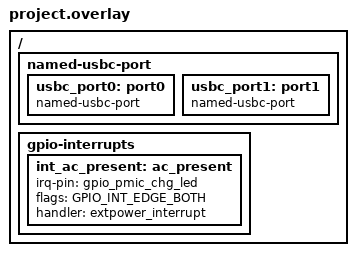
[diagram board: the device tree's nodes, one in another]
/* Copyright 2025 The ChromiumOS Authors
 * Use of this source code is governed by a BSD-style license that can be
 * found in the LICENSE file.
 */

/* bluey program common DTS includes */

#include <cros/integrated_fwid.dtsi>

#include "../interrupts.dtsi"
#include "../adc.dtsi"
#include "../i2c.dtsi"
#include "../common.dtsi"
#include "../battery.dtsi"
#include "../psl.dtsi"

/* quenbi project DTS includes */

#include "gpios.dtsi"
#include "fan.dtsi"
#include "keyboard.dtsi"
#include "temp_sensors.dtsi"

/* quenbi overrides follow... */

/ {
	named-usbc-port {
		usbc_port0: port0 {
			compatible = "named-usbc-port";
		};
		usbc_port1: port1 {
			compatible = "named-usbc-port";
		};
	};

	gpio-interrupts {
		int_ac_present: ac_present {
			irq-pin = <&gpio_pmic_chg_led>;
			flags = <GPIO_INT_EDGE_BOTH>;
			handler = "extpower_interrupt";
		};
	};
};
